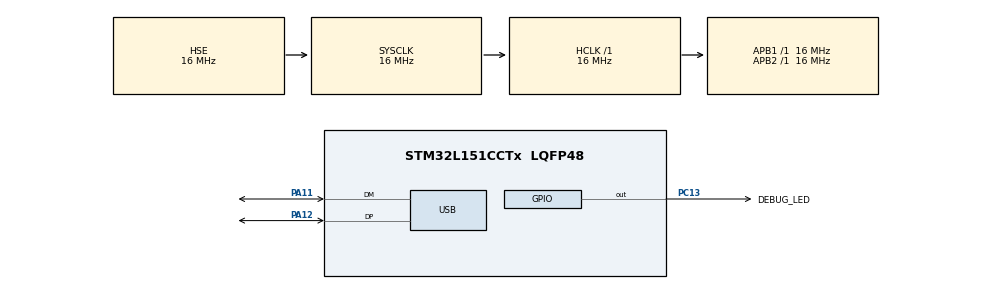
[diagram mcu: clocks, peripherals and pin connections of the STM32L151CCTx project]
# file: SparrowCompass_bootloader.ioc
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Mcu.Family=STM32L1
Mcu.Name=STM32L151CCTx
Mcu.Package=LQFP48
NVIC.PriorityGroup=NVIC_PRIORITYGROUP_4
NVIC.USB_HP_IRQn=true\:15\:0\:true\:false\:true\:true\:true\:true
NVIC.USB_LP_IRQn=true\:15\:0\:true\:false\:true\:false\:true\:true
PA11.Mode=Device
PA11.Signal=USB_DM
PA12.Mode=Device
PA12.Signal=USB_DP
PA13.Mode=Serial_Wire
PA13.Signal=SYS_JTMS-SWDIO
PA14.Mode=Serial_Wire
PA14.Signal=SYS_JTCK-SWCLK
PC13-WKUP2.GPIO_Label=DEBUG_LED
PC13-WKUP2.GPIO_ModeDefaultOutputPP=GPIO_MODE_OUTPUT_PP
PC13-WKUP2.GPIO_PuPd=GPIO_NOPULL
PC13-WKUP2.Signal=GPIO_Output
PH0-OSC_IN.Mode=HSE-External-Oscillator
PH0-OSC_IN.Signal=RCC_OSC_IN
PH1-OSC_OUT.Mode=HSE-External-Oscillator
PH1-OSC_OUT.Signal=RCC_OSC_OUT
ProjectManager.HeapSize=0x200
ProjectManager.StackSize=0x400
ProjectManager.TargetToolchain=STM32CubeIDE
RCC.48MHZClocksFreq_Value=48000000
RCC.AHBFreq_Value=16000000
RCC.APB1Freq_Value=16000000
RCC.APB1TimFreq_Value=16000000
RCC.APB2Freq_Value=16000000
RCC.APB2TimFreq_Value=16000000
RCC.HCLKFreq_Value=16000000
RCC.HSE_VALUE=16000000
RCC.HSI_VALUE=16000000
RCC.LSE_VALUE=32768
RCC.MSI_VALUE=2097000
RCC.PLLMUL=RCC_PLL_MUL6
RCC.SYSCLKFreq_VALUE=16000000
RCC.SYSCLKSource=RCC_SYSCLKSOURCE_HSE
RCC.VCOOutputFreq_Value=96000000
USB.low_power_enable=DISABLE
USB_DEVICE.CLASS_NAME_FS=DFU
USB_DEVICE.MANUFACTURER_STRING=Petzeectronics
USB_DEVICE.PRODUCT_STRING_DFU_FS=Sparrow Compass (DFU)
USB_DEVICE.USBD_DEBUG_LEVEL=3
USB_DEVICE.USBD_DFU_APP_DEFAULT_ADD=0x08008000
USB_DEVICE.USBD_DFU_MEDIA=@Internal Flash   /0x08000000/08*04Ka,056*04Kg
USB_DEVICE.USBD_DFU_XFER_SIZE=2048
USB_DEVICE.VirtualMode=Dfu
USB_DEVICE.VirtualModeFS=Dfu_FS
VP_USB_DEVICE_VS_USB_DEVICE_DFU_FS.Mode=DFU_FS
board=custom

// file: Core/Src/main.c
/* USER CODE BEGIN Header */
/**
 ******************************************************************************
 * @file           : main.c
 * @brief          : Main program body
 ******************************************************************************
 * @attention
 *
 * Copyright (c) 2025 STMicroelectronics.
 * All rights reserved.
 *
 * This software is licensed under terms that can be found in the LICENSE file
 * in the root directory of this software component.
 * If no LICENSE file comes with this software, it is provided AS-IS.
 *
 ******************************************************************************
 */
/* USER CODE END Header */
#include "main.h"
#include "usb_device.h"

/* USER CODE BEGIN PTD */
typedef void
(*pFunction) (void);
/* USER CODE END PTD */

/* USER CODE BEGIN PD */
#define DFU_BOOT_FLAG 0xDEADBEEF
/* USER CODE END PD */

/* USER CODE BEGIN PV */
extern int _bflag;
uint32_t *dfu_boot_flag;
pFunction JumpToApplication;
uint32_t JumpAddress;

/* USER CODE END PV */

void SystemClock_Config(void);
static void MX_GPIO_Init(void);

int main(void)
{

  /* USER CODE BEGIN 1 */
  // We handle all this before the HAL Libraries have been initialized.
  dfu_boot_flag = (uint32_t*) (&_bflag); // set in linker script

  if (*dfu_boot_flag != DFU_BOOT_FLAG)
    {

      /* Test if user code is programmed starting from address 0x08008000 */
      if (((*(__IO uint32_t*) USBD_DFU_APP_DEFAULT_ADD) & 0x2FFC0000)
	  == 0x20000000)
	{

	  /* Jump to user application */
	  JumpAddress = *(__IO uint32_t*) (USBD_DFU_APP_DEFAULT_ADD + 4);
	  JumpToApplication = (pFunction) JumpAddress;

	  /* Initialize user application's Stack Pointer */
	  __set_MSP (*(__IO uint32_t*) USBD_DFU_APP_DEFAULT_ADD);
	  JumpToApplication ();
	}

    }

  *dfu_boot_flag = 0; // So next boot won't be affected
  /* USER CODE END 1 */

  /* MCU Configuration--------------------------------------------------------*/

  /* Reset of all peripherals, Initializes the Flash interface and the Systick. */
  HAL_Init();

  /* Configure the system clock */
  SystemClock_Config();

  /* Initialize all configured peripherals */
  MX_GPIO_Init();
  MX_USB_DEVICE_Init();
  /* USER CODE BEGIN 2 */
  HAL_Delay (1000);
  /* USER CODE END 2 */

  /* Infinite loop */
  /* USER CODE BEGIN WHILE */
  while (1)
    {
      HAL_Delay (100);
      HAL_GPIO_WritePin (DEBUG_LED_GPIO_Port, DEBUG_LED_Pin, GPIO_PIN_RESET);
      HAL_Delay (100);
      HAL_GPIO_WritePin (DEBUG_LED_GPIO_Port, DEBUG_LED_Pin, GPIO_PIN_SET);
    /* USER CODE END WHILE */

    }
}

void SystemClock_Config(void)
{
  RCC_OscInitTypeDef RCC_OscInitStruct = {0};
  RCC_ClkInitTypeDef RCC_ClkInitStruct = {0};

  /** Configure the main internal regulator output voltage
  */
  __HAL_PWR_VOLTAGESCALING_CONFIG(PWR_REGULATOR_VOLTAGE_SCALE1);

  /** Initializes the RCC Oscillators according to the specified parameters
  * in the RCC_OscInitTypeDef structure.
  */
  RCC_OscInitStruct.OscillatorType = RCC_OSCILLATORTYPE_HSE;
  RCC_OscInitStruct.HSEState = RCC_HSE_ON;
  RCC_OscInitStruct.PLL.PLLState = RCC_PLL_ON;
  RCC_OscInitStruct.PLL.PLLSource = RCC_PLLSOURCE_HSE;
  RCC_OscInitStruct.PLL.PLLMUL = RCC_PLL_MUL6;
  RCC_OscInitStruct.PLL.PLLDIV = RCC_PLL_DIV2;
  if (HAL_RCC_OscConfig(&RCC_OscInitStruct) != HAL_OK)
  {
    Error_Handler();
  }

  /** Initializes the CPU, AHB and APB buses clocks
  */
  RCC_ClkInitStruct.ClockType = RCC_CLOCKTYPE_HCLK|RCC_CLOCKTYPE_SYSCLK
                              |RCC_CLOCKTYPE_PCLK1|RCC_CLOCKTYPE_PCLK2;
  RCC_ClkInitStruct.SYSCLKSource = RCC_SYSCLKSOURCE_HSE;
  RCC_ClkInitStruct.AHBCLKDivider = RCC_SYSCLK_DIV1;
  RCC_ClkInitStruct.APB1CLKDivider = RCC_HCLK_DIV1;
  RCC_ClkInitStruct.APB2CLKDivider = RCC_HCLK_DIV1;

  if (HAL_RCC_ClockConfig(&RCC_ClkInitStruct, FLASH_LATENCY_0) != HAL_OK)
  {
    Error_Handler();
  }
}

static void MX_GPIO_Init(void)
{
  GPIO_InitTypeDef GPIO_InitStruct = {0};

  /* GPIO Ports Clock Enable */
  __HAL_RCC_GPIOC_CLK_ENABLE();
  __HAL_RCC_GPIOH_CLK_ENABLE();
  __HAL_RCC_GPIOA_CLK_ENABLE();

  /*Configure GPIO pin Output Level */
  HAL_GPIO_WritePin(DEBUG_LED_GPIO_Port, DEBUG_LED_Pin, GPIO_PIN_RESET);

  /*Configure GPIO pin : DEBUG_LED_Pin */
  GPIO_InitStruct.Pin = DEBUG_LED_Pin;
  GPIO_InitStruct.Mode = GPIO_MODE_OUTPUT_PP;
  GPIO_InitStruct.Pull = GPIO_NOPULL;
  GPIO_InitStruct.Speed = GPIO_SPEED_FREQ_LOW;
  HAL_GPIO_Init(DEBUG_LED_GPIO_Port, &GPIO_InitStruct);

  /* USER CODE BEGIN MX_GPIO_Init_2 */
  HAL_GPIO_WritePin(GPIOA, GPIO_PIN_12, GPIO_PIN_RESET);

  /*Configure GPIO pin : DEBUG_LED_Pin */
  GPIO_InitStruct.Pin = GPIO_PIN_12;
  GPIO_InitStruct.Mode = GPIO_MODE_OUTPUT_PP;
  GPIO_InitStruct.Pull = GPIO_NOPULL;
  GPIO_InitStruct.Speed = GPIO_SPEED_FREQ_LOW;
  HAL_GPIO_Init(GPIOA, &GPIO_InitStruct);

  HAL_Delay(100);
  HAL_GPIO_WritePin(GPIOA, GPIO_PIN_12, GPIO_PIN_SET);   // Back high - so host will enumerate
  HAL_GPIO_DeInit(GPIOA, GPIO_PIN_12);
  /* USER CODE END MX_GPIO_Init_2 */
}

void Error_Handler(void)
{
  /* USER CODE BEGIN Error_Handler_Debug */
  /* User can add his own implementation to report the HAL error return state */
  __disable_irq ();
  while (1)
    {
    }
  /* USER CODE END Error_Handler_Debug */
}
